# RA2A1 register map
Vendor: Renesas Electronics Corporation; Series: RA2; File version: 1.1
CPU: other r1p0, little endian, MPU, no FPU, VTOR, 2 interrupt priority bits
Registers are 8-bit, read-write, reset 0x0 unless marked. A register's access mark holds for its fields unless they carry their own. Offsets are from the block's base; [hi:lo] are bit positions; 'fields as' and 'values as' point back to an identical list; <NAME> marks a mode.

## ACMPLP — Low-Power Analog Comparator
Base 0x40085E00
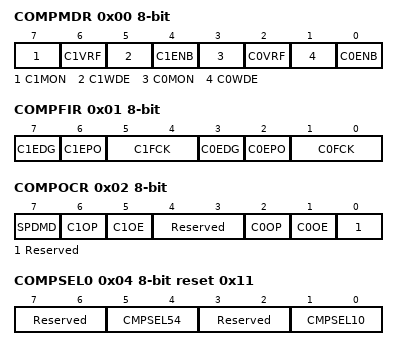
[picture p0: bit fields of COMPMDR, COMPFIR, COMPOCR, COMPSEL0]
0x00 COMPMDR — ACMPLP Mode Setting Register
  [7] C1MON — ACMPLP1 Monitor Flag
    0=IVCMP1 < Comparator1 Reference level(When the window function is disabled)/IVCMP1 < IVREF0 or IVCMP1 > IVREF1(When the window function is enabled); 1=IVCMP1 > Comparator1 Reference level(When the window function is disabled)/IVREF0 < IVCMP1 < IVREF1(When the window function is enabled)
  [6] C1VRF — ACMPLP1 Reference Voltage SelectionNote1: It's effective only at the time of standard mode.IVREF0 and IVREF1 are chosen at window mode condition in spite of setting of this bit.
    0=CMPREF1 input; 1=internal reference voltage (Vref)
  [5] C1WDE — ACMPLP1 Window Function Mode Enable
    0=Disabled; 1=Enabled
  [4] C1ENB — ACMPLP1 Operation Enable
    0=Disabled; 1=Enabled
  [3] C0MON — ACMPLP0 Monitor Flag
    0=IVCMP0 < Comparator0 Reference level(When the window function is disabled)/IVCMP0 < IVREF0 or IVCMP0 > IVREF1(When the window function is enabled); 1=IVCMP0 > Comparator0 Reference level(When the window function is disabled)/IVREF0 < IVCMP0 < IVREF1(When the window function is enabled)
  [2] C0VRF — ACMPLP0 Reference Voltage SelectionNote1: It's effective only at the time of standard mode.IVREF0 and IVREF1 are chosen at window mode condition in spite of setting of this bit.
    0=CMPREF0 input; 1=internal reference voltage (Vref)
  [1] C0WDE — ACMPLP0 Window Function Mode Enable
    0=Disabled; 1=Enabled
  [0] C0ENB — ACMPLP0 Operation Enable
    0=Disabled; 1=Enabled
0x01 COMPFIR — ACMPLP Filter Control Register
  [7] C1EDG — ACMPLP1 Filter Select
    0=Interrupt and ELC event request by one-edge detection; 1=Interrupt and ELC event request by both-edge detection
  [6] C1EPO — ACMPLP1 Edge Polarity Switching
    0=Interrupt and ELC event request at rising edge; 1=Interrupt and ELC event request at falling edge
  [5:4] C1FCK — ACMPLP1 Edge Detection Selection
    0=No Sampling (bypass); 1=Sampling at PCLK; 2=Sampling at PCLK/8; 3=Sampling at PCLK/32
  [3] C0EDG — ACMPLP0 Filter Select
    values as C1EDG
  [2] C0EPO — ACMPLP0 Edge Polarity Switching
    values as C1EPO
  [1:0] C0FCK — ACMPLP0 Edge Detection Selection
    values as C1FCK
0x02 COMPOCR — ACMPLP Output Control Register
  [7] SPDMD — ACMPLP0/ACMPLP1 Speed Selection
    0=Comparator low-speed mode; 1=Comparator high-speed mode
  [6] C1OP — ACMPLP1 VCOUT Output Polarity Selection
    0=Non inverted; 1=Inverted
  [5] C1OE — ACMPLP1 VCOUT Pin Output Enable
    0=Disabled; 1=Enabled
  [4:3] Reserved — These bits are read as 00. The write value should be 00.
  [2] C0OP — ACMPLP0 VCOUT Output Polarity Selection
    0=Non inverted; 1=Inverted
  [1] C0OE — ACMPLP0 VCOUT Pin Output Enable
    0=Disabled; 1=Enabled
  [0] Reserved — This bit is read as 0. The write value should be 0.
0x04 COMPSEL0 reset 0x11 — Comparator Input Select Register
  [7:6] Reserved — These bits are read as 00. The write value should be 00.
  [5:4] CMPSEL54 — ACMPLP1 Input (IVCMP1) Selection
    0=No input; 1=CMPIN1 input selected; 2=AMP1O output selected
  [3:2] Reserved — These bits are read as 00. The write value should be 00.
  [1:0] CMPSEL10 — ACMPLP0 Input (IVCMP0) Selection
    0=No input; 1=CMPIN0 input selected; 2=AMP0O output selected
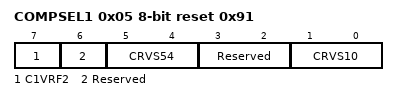
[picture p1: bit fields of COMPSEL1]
0x05 COMPSEL1 reset 0x91 — Comparator Reference voltage Select Register
  [7] C1VRF2 — ACMPLP1 Reference Voltage Selection
    0=IVREF0 selected; 1=IVREF1 selected
  [6] Reserved — This bit is read as 0. The write value should be 0.
  [5:4] CRVS54 — ACMPLP1 Reference Voltage(IVREF1) Selection
    0=No reference voltage; 1=CMPREF1 selected; 2=DA8_1 output selected
  [3:2] Reserved — These bits are read as 00. The write value should be 00.
  [1:0] CRVS10 — ACMPLP0 Reference Voltage (IVREF0) Selection
    0=No reference voltage; 1=CMPREF0 selected; 2=DA8_0 output selected

## Notices in the file
This software is supplied by Renesas Electronics Corporation and is only intended for
use with Renesas products. No other uses are authorized. This software is owned by
Renesas Electronics Corporation and is protected under all applicable laws, including
copyright laws.
THIS SOFTWARE IS PROVIDED "AS IS" AND RENESAS MAKES NO WARRANTIES REGARDING
THIS SOFTWARE, WHETHER EXPRESS, IMPLIED OR STATUTORY, INCLUDING BUT NOT LIMITED TO
WARRANTIES OF MERCHANTABILITY, FITNESS FOR A PARTICULAR PURPOSE AND NON-INFRINGEMENT.
ALL SUCH WARRANTIES ARE EXPRESSLY DISCLAIMED. TO THE MAXIMUM EXTENT PERMITTED NOT
PROHIBITED BY LAW, NEITHER RENESAS ELECTRONICS CORPORATION NOR ANY OF ITS AFFILIATED
COMPANIES SHALL BE LIABLE FOR ANY DIRECT, INDIRECT, SPECIAL, INCIDENTAL OR CONSEQUENTIAL
DAMAGES FOR ANY REASON RELATED TO THIS SOFTWARE, EVEN IF RENESAS OR ITS AFFILIATES HAVE
BEEN ADVISED OF THE POSSIBILITY OF SUCH DAMAGES.
Renesas reserves the right, without notice, to make changes to this software and to
discontinue the availability of this software. By using this software, you agree to
the additional terms and conditions found by accessing the following link:
http://www.renesas.com/disclaimer
